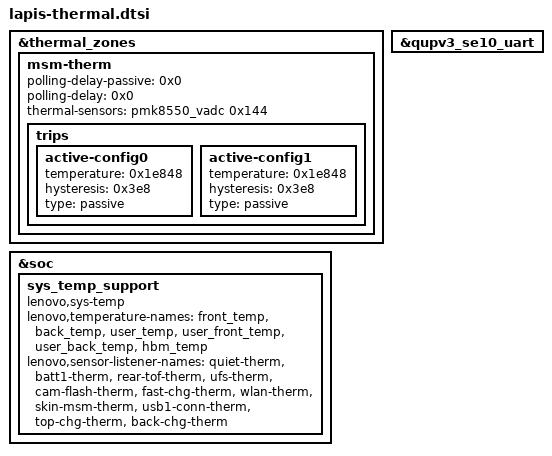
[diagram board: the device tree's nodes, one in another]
// SPDX-License-Identifier: GPL-2.0-only
/*
 * (C) 2026 The LineageOS Project
 *
 * lapis: thermal
 * Reconstructed from the Lenovo TB520FU stock dtbo (ZUI 18.5.10.037).
 */

&thermal_zones {

	msm-therm {
		polling-delay-passive = <0x0>;
		polling-delay = <0x0>;
		thermal-sensors = <&pmk8550_vadc 0x144>;

		trips {

			active-config0 {
				temperature = <0x1e848>;
				hysteresis = <0x3e8>;
				type = "passive";
			};

			active-config1 {
				temperature = <0x1e848>;
				hysteresis = <0x3e8>;
				type = "passive";
			};
		};
	};
};

&soc {

	sys_temp_support {
		compatible = "lenovo,sys-temp";
		lenovo,temperature-names = "front_temp", "back_temp", "user_temp", "user_front_temp", "user_back_temp", "hbm_temp";
		lenovo,sensor-listener-names = "quiet-therm", "batt1-therm", "rear-tof-therm", "ufs-therm", "cam-flash-therm", "fast-chg-therm", "wlan-therm", "skin-msm-therm", "usb1-conn-therm", "top-chg-therm", "back-chg-therm";
	};
};

&qupv3_se10_uart {
	status = "ok";
};
